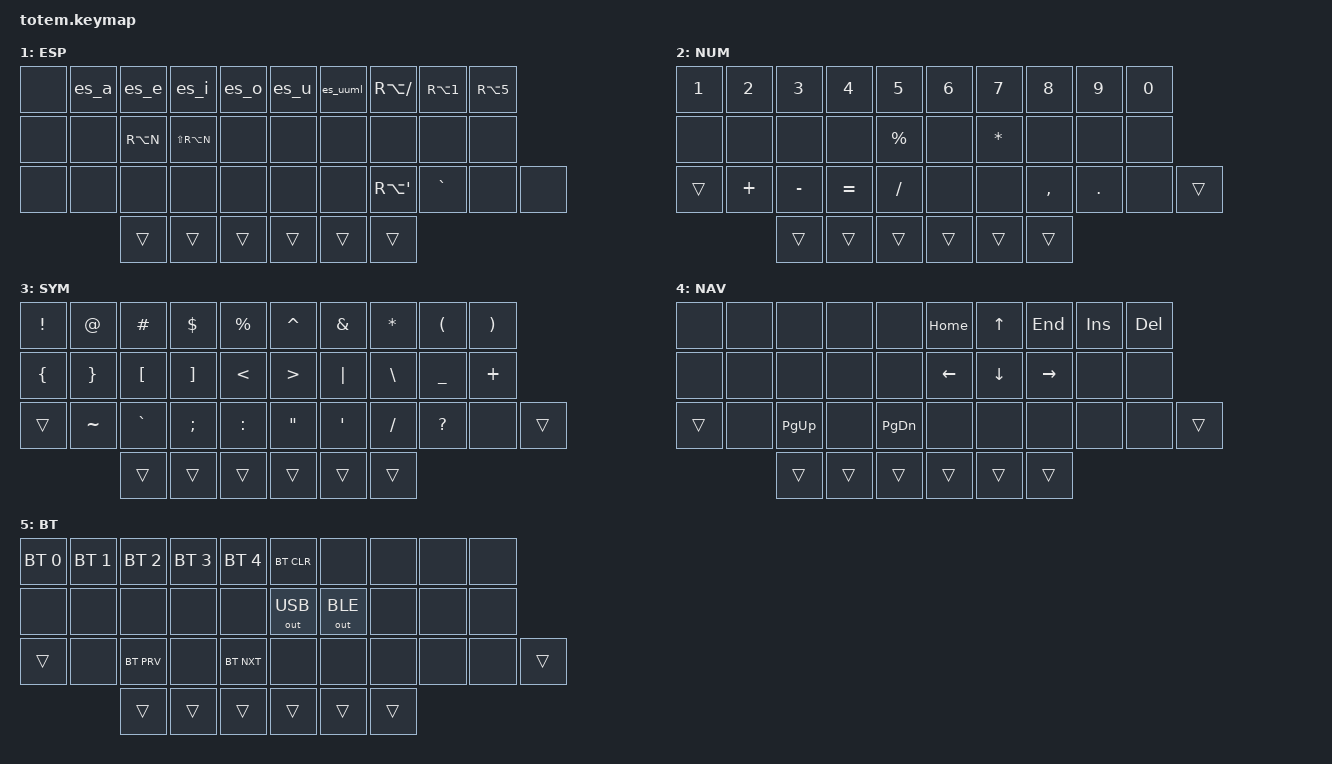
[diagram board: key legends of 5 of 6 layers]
//
//                                                        ▀▀▀▀▀     ▀▀▀▀▀          ▀▀█▀▀
//                                                        ▄▀▀▀▄  ▄  ▄▀▀▀▄  ▄  ▄▀▀▀▄  █  ▄▀▀▀▄
//                                                        █   █  █  █   █  █  █   █  █  █   █
//                                                         ▀▀▀   █   ▀▀▀   █   ▀▀▀   ▀   ▀▀▀
//                                                               █      ▄▄▄█▄▄▄    █   █  
//                                                               ▀      █  █  █     █▄█
//                                                             ▀▀▀▀▀    █  █  █      ▀
//                                                                      ▀  ▀  ▀
//
// ▄▄▄▄▄▄▄▄▄▄▄▄▄▄▄▄▄▄▄▄▄▄▄▄▄▄▄▄▄▄▄▄▄▄▄▄▄▄▄▄▄▄▄▄▄▄▄▄▄▄▄▄▄▄▄▄▄▄▄▄▄▄▄▄▄▄▄▄▄▄▄▄▄▄▄▄▄▄▄▄▄▄▄▄▄▄▄▄▄▄▄▄▄▄▄▄▄▄▄▄▄▄▄▄▄▄▄▄▄▄▄▄▄▄▄▄▄▄▄▄▄▄▄▄▄▄▄▄▄▄▄▄▄▄▄▄▄▄▄▄▄▄▄▄▄▄▄▄▄
// TOTEM ES Edition — US ANSI BASE + Spanish / symbols / navigation / Bluetooth layers
// Spanish output assumes US International keyboard layout on the host OS.

#include <behaviors.dtsi>
#include <dt-bindings/zmk/keys.h>
#include <dt-bindings/zmk/bt.h>
#include <dt-bindings/zmk/outputs.h>

#define BASE 0
#define ESP  1
#define NUM  2
#define SYM  3
#define NAV  4
#define BT   5

/ {
    behaviors {
        lt_sym_bt: layer_tap_sym_bt {
            label = "LT_SYM_BT";
            compatible = "zmk,behavior-hold-tap";
            #binding-cells = <2>;
            tapping-term-ms = <200>;
            flavor = "tap-preferred";
            bindings = <&mo>, <&mo>;
        };
    };

    macros {
        es_a: es_a {
            label = "ES_A";
            compatible = "zmk,behavior-macro";
            #binding-cells = <0>;
            bindings = <&macro_tap &kp SQT &kp A>;  // á
        };
        es_e: es_e {
            label = "ES_E";
            compatible = "zmk,behavior-macro";
            #binding-cells = <0>;
            bindings = <&macro_tap &kp SQT &kp E>;  // é
        };
        es_i: es_i {
            label = "ES_I";
            compatible = "zmk,behavior-macro";
            #binding-cells = <0>;
            bindings = <&macro_tap &kp SQT &kp I>;  // í
        };
        es_o: es_o {
            label = "ES_O";
            compatible = "zmk,behavior-macro";
            #binding-cells = <0>;
            bindings = <&macro_tap &kp SQT &kp O>;  // ó
        };
        es_u: es_u {
            label = "ES_U";
            compatible = "zmk,behavior-macro";
            #binding-cells = <0>;
            bindings = <&macro_tap &kp SQT &kp U>;  // ú
        };
        es_uuml: es_uuml {
            label = "ES_UUML";
            compatible = "zmk,behavior-macro";
            #binding-cells = <0>;
            bindings = <&macro_tap &kp LS(SQT) &kp U>;  // ü
        };
    };

    keymap {
        compatible = "zmk,keymap";

        base_layer {
            label = "BASE";
            bindings = <
            &kp Q       &kp W      &kp E       &kp R       &kp T                                       &kp Y       &kp U       &kp I       &kp O      &kp P
            &kp A       &kp S      &kp D       &kp F       &kp G                                       &kp H       &kp J       &kp K       &kp L      &kp SEMI
&lt SYM ESC  &kp Z       &kp X      &kp C       &kp V       &kp B                                       &kp N       &kp M       &kp COMMA   &kp DOT    &kp FSLH   &lt ESP BSPC
                                   &lt ESP LGUI &mo NAV    &kp SPACE                                   &kp RET     &mo NUM     &lt_sym_bt BT SYM
            >;
        };

        esp_layer {
            label = "ESP";
            bindings = <
            &none       &es_a      &es_e       &es_i       &es_o                                       &es_u       &es_uuml    &kp RA(FSLH) &kp RA(N1) &kp RA(N5)
            &none       &none      &kp RA(N)   &kp LS(RA(N)) &none                                     &none       &none       &none       &none      &none
            &none       &none      &none       &none       &none                                       &none       &none       &kp RA(SQT) &kp GRAVE  &none      &none
                                   &trans      &trans      &trans                                      &trans      &trans      &trans
            >;
        };

        num_layer {
            label = "NUM";
            bindings = <
            &kp N1      &kp N2     &kp N3      &kp N4      &kp N5                                      &kp N6      &kp N7      &kp N8      &kp N9     &kp N0
            &none       &none      &none       &none       &kp PRCNT                                   &none       &kp STAR    &none       &none      &none
            &trans      &kp PLUS   &kp MINUS   &kp EQUAL   &kp SLASH                                   &none       &none       &kp COMMA   &kp DOT    &none      &trans
                                   &trans      &trans      &trans                                      &trans      &trans      &trans
            >;
        };

        sym_layer {
            label = "SYM";
            bindings = <
            &kp EXCL    &kp AT     &kp HASH    &kp DLLR    &kp PRCNT                                   &kp CARET   &kp AMPS    &kp STAR    &kp LPAR   &kp RPAR
            &kp LBRC    &kp RBRC   &kp LBKT    &kp RBKT    &kp LT                                      &kp GT      &kp PIPE    &kp BSLH    &kp UNDER  &kp PLUS
            &trans      &kp TILDE  &kp GRAVE   &kp SEMI    &kp COLON                                   &kp DQT     &kp SQT     &kp FSLH    &kp QUESTION &none    &trans
                                   &trans      &trans      &trans                                      &trans      &trans      &trans
            >;
        };

        nav_layer {
            label = "NAV";
            bindings = <
            &none       &none      &none       &none       &none                                       &kp HOME    &kp UP      &kp END     &kp INS    &kp DEL
            &none       &none      &none       &none       &none                                       &kp LEFT    &kp DOWN    &kp RIGHT   &none      &none
            &trans      &none      &kp PG_UP   &none       &kp PG_DN                                   &none       &none       &none       &none      &none      &trans
                                   &trans      &trans      &trans                                      &trans      &trans      &trans
            >;
        };

        bt_layer {
            label = "BT";
            bindings = <
            &bt BT_SEL 0 &bt BT_SEL 1 &bt BT_SEL 2 &bt BT_SEL 3 &bt BT_SEL 4                            &bt BT_CLR  &none       &none       &none      &none
            &none       &none      &none       &none       &none                                       &out OUT_USB &out OUT_BLE &none      &none      &none
            &trans      &none      &bt BT_PRV  &none       &bt BT_NXT                                  &none       &none       &none       &none      &none      &trans
                                   &trans      &trans      &trans                                      &trans      &trans      &trans
            >;
        };
    };
};
